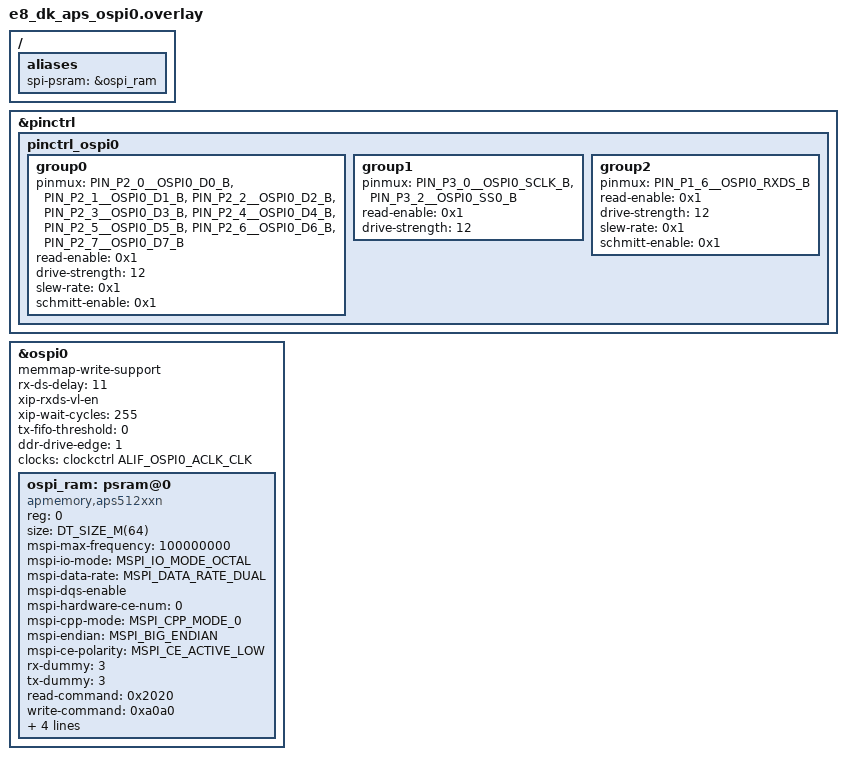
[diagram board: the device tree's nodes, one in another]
/* Copyright (C) 2025 Alif Semiconductor - All Rights Reserved.
 * Use, distribution and modification of this code is permitted under the
 * terms stated in the Alif Semiconductor Software License Agreement
 *
 * You should have received a copy of the Alif Semiconductor Software
 * License Agreement with this file. If not, please write to:
 * contact@alifsemi.com, or visit: https://alifsemi.com/license
 */

/*
 * For OSPI0 Test with APS512XXN RAM
 */

/ {
	aliases {
		spi-psram = &ospi_ram;
	};
};

&pinctrl {
	pinctrl_ospi0:pinctrl_ospi0 {
		group0 {
			pinmux = <PIN_P2_0__OSPI0_D0_B>,
				 <PIN_P2_1__OSPI0_D1_B>,
				 <PIN_P2_2__OSPI0_D2_B>,
				 <PIN_P2_3__OSPI0_D3_B>,
				 <PIN_P2_4__OSPI0_D4_B>,
				 <PIN_P2_5__OSPI0_D5_B>,
				 <PIN_P2_6__OSPI0_D6_B>,
				 <PIN_P2_7__OSPI0_D7_B>;
			read-enable = <0x1>;
			drive-strength = <12>;
			slew-rate = <0x1>;
			schmitt-enable = <0x1>;
		};
		group1 {
			pinmux = <PIN_P3_0__OSPI0_SCLK_B>,
				 <PIN_P3_2__OSPI0_SS0_B>;
			read-enable = <0x1>;
			drive-strength = <12>;
		};
		group2 {
			pinmux = <PIN_P1_6__OSPI0_RXDS_B>;
			read-enable = <0x1>;
			drive-strength = <12>;
			slew-rate = <0x1>;
			schmitt-enable = <0x1>;
		};
	};
};

&ospi0 {
	memmap-write-support;
	rx-ds-delay = <11>;
	xip-rxds-vl-en;
	xip-wait-cycles = <255>;
	tx-fifo-threshold = <0>;
	ddr-drive-edge = <1>;
	clocks = <&clockctrl ALIF_OSPI0_ACLK_CLK>;
	status = "okay";

	ospi_ram: psram@0 {
		compatible = "apmemory,aps512xxn";
		reg = <0>;
		size = <DT_SIZE_M(64)>;
		mspi-max-frequency = <100000000>;
		mspi-io-mode = "MSPI_IO_MODE_OCTAL";
		mspi-data-rate = "MSPI_DATA_RATE_DUAL";
		mspi-dqs-enable;
		mspi-hardware-ce-num = <0>;
		mspi-cpp-mode = "MSPI_CPP_MODE_0";
		mspi-endian = "MSPI_BIG_ENDIAN";
		mspi-ce-polarity = "MSPI_CE_ACTIVE_LOW";
		rx-dummy = <3>;
		tx-dummy = <3>;
		read-command = <0x2020>;
		write-command = <0xa0a0>;
		command-length = "INSTR_2_BYTE";
		address-length = "ADDR_4_BYTE";
		xip-config = <1 0x0 DT_SIZE_M(64) 0>;
		latency-code = <4>;
		status = "okay";
	};
};
